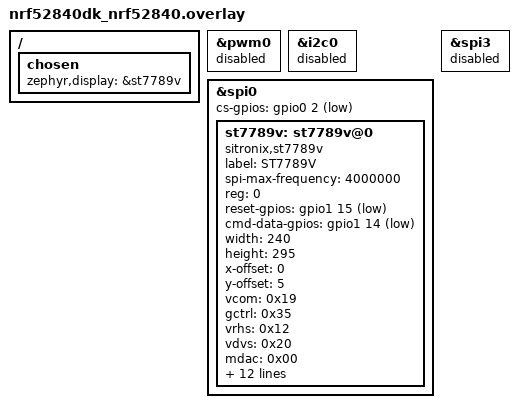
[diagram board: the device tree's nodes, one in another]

/ {
    chosen {
        zephyr,display = &st7789v;
    };
};
&pwm0 {
    status = "disabled";
};
&i2c0 {
    status = "disabled";
};

&spi0 {
    cs-gpios = <&gpio0 2 GPIO_ACTIVE_LOW>;
    st7789v: st7789v@0 {
        compatible = "sitronix,st7789v";
        label = "ST7789V";
        spi-max-frequency = <4000000>;
        reg = <0>;
        reset-gpios = <&gpio1 15 GPIO_ACTIVE_LOW>;
        cmd-data-gpios = <&gpio1 14 GPIO_ACTIVE_LOW>;
        width = <240>;
        height = <295>;
        x-offset = <0>;
        y-offset = <5>;
        vcom = <0x19>;
        gctrl = <0x35>;
        vrhs = <0x12>;
        vdvs = <0x20>;
        mdac = <0x00>;
        lcm = <0x2c>;
        colmod = <0x05>;
        gamma = <0x01>;
        porch-param = [ 0c 0c 00 33 33  ];
        cmd2en-param = [ 5a 69 02 01  ];
        pwctrl1-param = [ a4 a1  ];
        pvgam-param = [ D0 04 0D 11 13 2B 3F 54 4C 18 0D 0B 1F 23  ];
        nvgam-param = [ D0 04 0C 11 13 2C 3F 44 51 2F 1F 1F 20 23  ];
        ram-param = [ 00 F0  ];
        rgb-param = [ CD 08 14  ];

    };
    status = "okay";
};
&spi3 {
    status = "disabled";
};
